# DSSUL_0_CFG register map
Vendor: Texas Instruments
Peripheral module from a debugger description file (folder 66AK2G0x_66AK2G1x).
Registers are 32-bit, access per field, reset values left out (the file's numbers can be read two ways) unless marked. A register's access mark holds for its fields unless they carry their own. Offsets are as the file gives them; lines under a group give offsets from that group; [hi:lo] are bit positions; {n}, {i} and the like mark numbered series; 'fields as' and 'values as' point back to an identical list; <NAME> marks a mode.

## DSSUL_0_CFG
0x00 DSS_REVISION ro
  [31:0] REVISION — TI internal data. Identifies revision of peripheral.
0x10 DSS_SYSCONFIG
  [1:0] SIDLEMODE rw — 0h (R/W) = Force-idle. An idle request is acknowledged unconditionally. 1h (R/W) = No-idle. An idle request is never acknowledged. 2h (R/W) = Smart-idle. Acknowledgement to an idle request is given based on the internal activity of the module. 3h (R/W) = Reserved
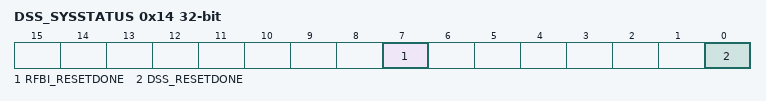
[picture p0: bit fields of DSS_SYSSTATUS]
0x14 DSS_SYSSTATUS ro
  [7] RFBI_RESETDONE — Reset status of RFBI module 0h (R) = Internal module reset is on-going 1h (R) = Reset completed
  [0] DSS_RESETDONE — Reset status of DISPC/DSS 0h (R) = Internal module reset is on-going 1h (R) = Reset completed
0x18 DSS_RFBI_CTRL
  [0] RFBI_ENABLE rw — RFBI Enable. This bit is used to control the RFBI module. 0h (R/W) = Disable 1h (R/W) = Enable
0x1C DSS_DPI_CTRL
  [0] DPI_ENABLE rw — Enable DPI interface. This bit is used to enable the DPI interface. 0h (R/W) = Disable - PCLK is gated 1h (R/W) = Enable
0x40 DSS_DEBUG_CFG
  [2:0] CFG rw — Defines which debug bus to provide on the DSS debug bus connected at the top. Only value 0 can be used in this family of devices. 0h (R/W) = Select DISPC Debug bus
